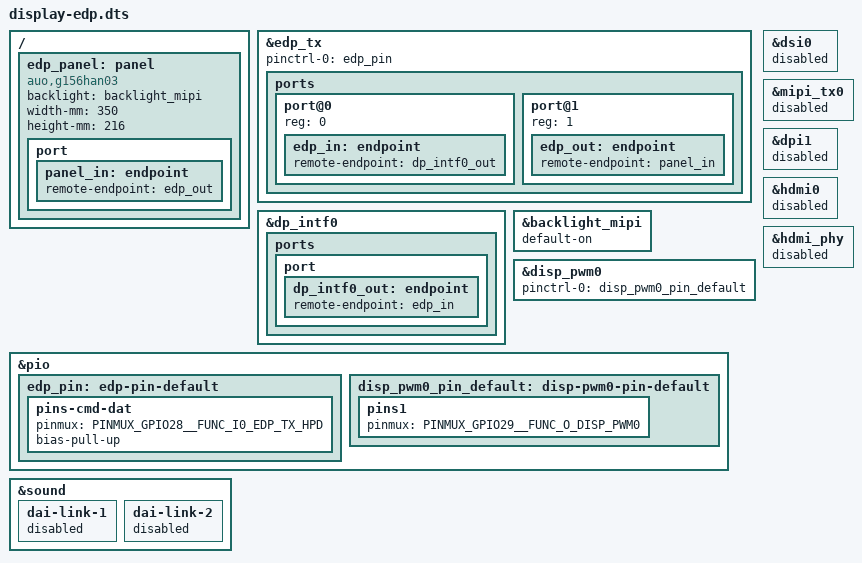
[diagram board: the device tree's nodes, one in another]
/dts-v1/;
/plugin/;

#include <dt-bindings/pinctrl/mediatek,mt8188-pinfunc.h>
#include <dt-bindings/gpio/gpio.h>

/ {
	fragment@0 {
		target = <&edp_tx>;
		__overlay__ {
			pinctrl-names = "default";
			pinctrl-0 = <&edp_pin>;
			status = "okay";

			ports {
				#address-cells = <1>;
				#size-cells = <0>;

				port@0 {
					reg = <0>;
					edp_in: endpoint {
					remote-endpoint = <&dp_intf0_out>;
					};
				};

				port@1 {
					reg = <1>;
					edp_out: endpoint {
						remote-endpoint = <&panel_in>;
					};
				};
			};
		};
	};

	fragment@1 {
		target = <&dp_intf0>;
		__overlay__ {
			status = "okay";
			ports {
				port {
					dp_intf0_out: endpoint {
						remote-endpoint = <&edp_in>;
					};
				};
			};
		};
	};

	fragment@2 {
		target-path = "/";
		__overlay__ {
			edp_panel: panel {
				compatible = "auo,g156han03";
				backlight = <&backlight_mipi>;
				width-mm = <350>;
				height-mm = <216>;
				status = "okay";

				port {
					panel_in: endpoint {
						remote-endpoint = <&edp_out>;
					};
				};
			};
		};
	};

	fragment@4 {
		target = <&backlight_mipi>;
		__overlay__ {
			default-on;
			status = "okay";
		};
	};

	fragment@5 {
		target = <&disp_pwm0>;
		__overlay__ {
			status = "okay";
			pinctrl-names = "default";
			pinctrl-0 = <&disp_pwm0_pin_default>;
		};
	};

	fragment@6 {
		target = <&pio>;
		__overlay__ {
			edp_pin: edp-pin-default {
				pins-cmd-dat {
					pinmux = <PINMUX_GPIO28__FUNC_I0_EDP_TX_HPD>;	/* DSI1_TE */
					bias-pull-up;
				};
			};

			disp_pwm0_pin_default: disp-pwm0-pin-default {
				pins1 {
					pinmux = <PINMUX_GPIO29__FUNC_O_DISP_PWM0>;
				};
			};
		};
	};

	fragment@7 {
		target = <&dsi0>;
		__overlay__ {
			status = "disabled";
		};
	};

	fragment@8 {
		target = <&mipi_tx0>;
		__overlay__ {
			status = "disabled";
		};
	};

	fragment@9 {
		target = <&dpi1>;
		__overlay__ {
			status = "disabled";
		};
	};

	fragment@10 {
		target = <&hdmi0>;
		__overlay__ {
			status = "disabled";
		};
	};

	fragment@11 {
		target = <&hdmi_phy>;
		__overlay__ {
			status = "disabled";
		};
	};

	fragment@12 {
		target = <&sound>;
		__overlay__ {
			dai-link-1 { /* HDMI */
				status = "disabled";
			};

			dai-link-2 { /* DPTX */
				status = "disabled";
			};
		};
	};
};
